# STM32H533 register map
File version: 1.3
CPU: CM33 r0p0, little endian, MPU, FPU, 4 interrupt priority bits
Registers are 32-bit, read-write, reset 0x0 unless marked. A register's access mark holds for its fields unless they carry their own. Offsets are from the block's base; [hi:lo] are bit positions; {n}, {i} and the like mark numbered series.

## ADCC — ADC common registers block
Base 0x42028300
Same registers: SEC_ADCC 0x52028300
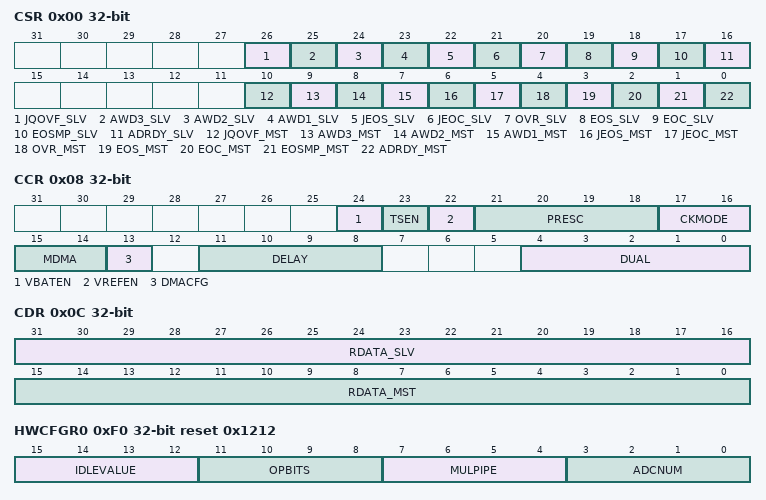
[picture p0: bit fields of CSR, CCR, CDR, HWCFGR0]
0x00 CSR ro — ADC common status register
  [26] JQOVF_SLV — Injected Context Queue Overflow flag of the slave ADC
  [25] AWD3_SLV — Analog watchdog 3 flag of the slave ADC
  [24] AWD2_SLV — Analog watchdog 2 flag of the slave ADC
  [23] AWD1_SLV — Analog watchdog 1 flag of the slave ADC
  [22] JEOS_SLV — End of injected sequence flag of the slave ADC
  [21] JEOC_SLV — End of injected conversion flag of the slave ADC
  [20] OVR_SLV — Overrun flag of the slave ADC
  [19] EOS_SLV — End of regular sequence flag of the slave ADC.
  [18] EOC_SLV — End of regular conversion of the slave ADC
  [17] EOSMP_SLV — End of Sampling phase flag of the slave ADC
  [16] ADRDY_SLV — Slave ADC ready
  [10] JQOVF_MST — Injected Context Queue Overflow flag of the master ADC
  [9] AWD3_MST — Analog watchdog 3 flag of the master ADC
  [8] AWD2_MST — Analog watchdog 2 flag of the master ADC
  [7] AWD1_MST — Analog watchdog 1 flag of the master ADC
  [6] JEOS_MST — End of injected sequence flag of the master ADC
  [5] JEOC_MST — End of injected conversion flag of the master ADC
  [4] OVR_MST — Overrun flag of the master ADC
  [3] EOS_MST — End of regular sequence flag of the master ADC
  [2] EOC_MST — End of regular conversion of the master ADC
  [1] EOSMP_MST — End of Sampling phase flag of the master ADC
  [0] ADRDY_MST — Master ADC ready
0x08 CCR — ADC common control register
  [24] VBATEN — VBAT enable
  [23] TSEN — Vless thansub>SENSEless than/sub> enable
  [22] VREFEN — Vless thansub>REFINTless than/sub> enable
  [21:18] PRESC — ADC prescaler
  [17:16] CKMODE — ADC clock mode
  [15:14] MDMA — Direct memory access mode for dual ADC mode
  [13] DMACFG — DMA configuration (for dual ADC mode)
  [11:8] DELAY — Delay between 2 sampling phases
  [4:0] DUAL — Dual ADC mode selection
0x0C CDR ro — ADC common regular data register for dual mode
  [31:16] RDATA_SLV — Regular data of the slave ADC
  [15:0] RDATA_MST — Regular data of the master ADC.
0xF0 HWCFGR0 ro reset 0x1212 — ADC hardware configuration register
  [15:12] IDLEVALUE — Idle value for non-selected channels
  [11:8] OPBITS — Number of option bits
  [7:4] MULPIPE — Number of pipeline stages
  [3:0] ADCNUM — Number of ADCs implemented
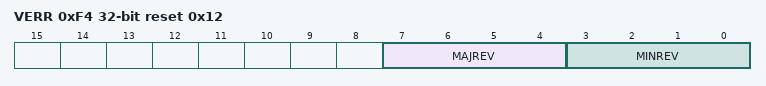
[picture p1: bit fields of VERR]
0xF4 VERR ro reset 0x12 — ADC version register
  [7:4] MAJREV — Major revision
  [3:0] MINREV — Minor revision
0xF8 IPDR ro reset 0x110006 — ADC identification register
  [31:0] ID — Peripheral identifier
0xFC SIDR ro reset 0xA3C5DD01 — ADC size identification register
  [31:0] SID — Size Identification

## AES — AES register block
Base 0x420C0000
Same registers: AES_S 0x520C0000
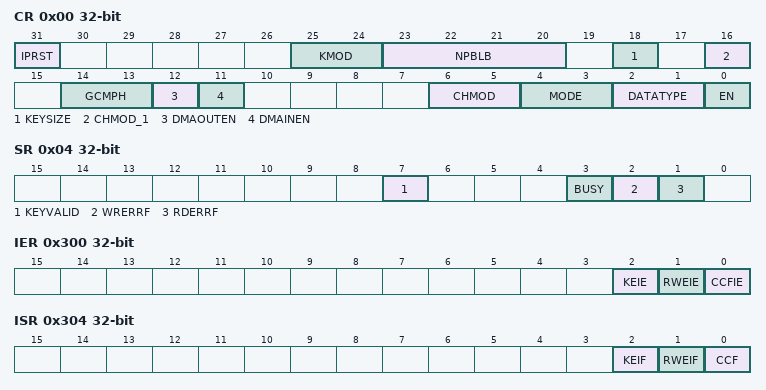
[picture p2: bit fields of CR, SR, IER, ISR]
0x00 CR — AES control register
  [31] IPRST — AES peripheral software reset
  [25:24] KMOD — Key mode selection
  [23:20] NPBLB — Number of padding bytes in last block
  [18] KEYSIZE — Key size selection
  [16] CHMOD_1 — CHMOD[2]
  [14:13] GCMPH — GCM or CCM phase selection
  [12] DMAOUTEN — DMA output enable
  [11] DMAINEN — DMA input enable
  [6:5] CHMOD — CHMOD[1:0]: Chaining mode
  [4:3] MODE — Operating mode
  [2:1] DATATYPE
  [0] EN — Enable
0x04 SR ro — AES status register
  [7] KEYVALID — Key valid flag
  [3] BUSY
  [2] WRERRF — Write error flag
  [1] RDERRF — Read error flag
0x08 DINR wo — AES data input register
  [31:0] DIN — Data input
0x0C DOUTR ro — AES data output register
  [31:0] DOUT — Data output
{0x10+4i} KEYR{i} wo (i=0..3) — AES key register {i}
  [31:0] KEY — Cryptographic key, bits [{32i+31}:{32i}]
{0x20+4i} IVR{i} (i=0..3) — AES initialization vector register {i}
  [31:0] IVI — Initialization vector input, bits [{32i+31}:{32i}]
{0x20+4i} KEYR{i} wo (i=4..7) — AES key register {i}
  [31:0] KEY — Cryptographic key, bits [{32i+31}:{32i}]
{0x40+4i} SUSPR{i} (i=0..7) — AES suspend registers
  [31:0] SUSP — Suspend data
0x300 IER — AES interrupt enable register
  [2] KEIE — Key error interrupt enable
  [1] RWEIE — Read or write error interrupt enable
  [0] CCFIE — Computation complete flag interrupt enable
0x304 ISR ro — AES interrupt status register
  [2] KEIF — Key error interrupt flag
  [1] RWEIF — Read or write error interrupt flag
  [0] CCF — Computation complete flag
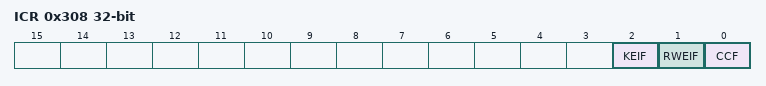
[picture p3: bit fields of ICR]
0x308 ICR wo — AES interrupt clear register
  [2] KEIF — Key error interrupt flag clear
  [1] RWEIF — Read or write error interrupt flag clear
  [0] CCF — Computation complete flag clear

## SAES — SAES register block
Base 0x420C0C00
Same registers: SAES_S 0x520C0C00
Registers as AES (with AES read as SAES); these are added or differ:
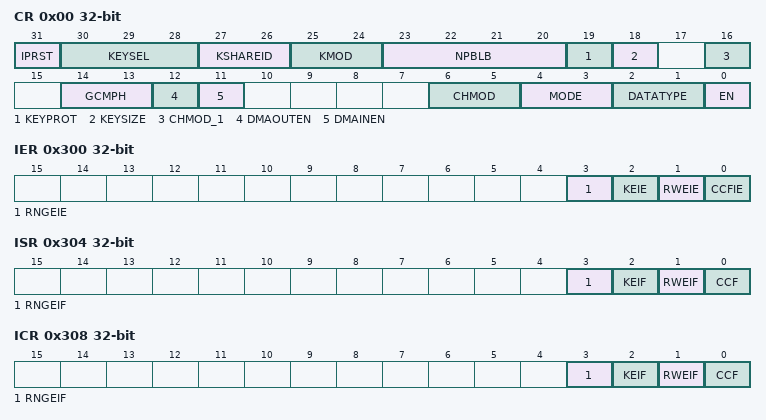
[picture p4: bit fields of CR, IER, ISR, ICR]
0x00 CR — SAES control register
  [31] IPRST — SAES peripheral software reset
  [30:28] KEYSEL — Key selection
  [27:26] KSHAREID — Key share identification
  [25:24] KMOD — Key mode selection
  [23:20] NPBLB — Number of padding bytes in last block
  [19] KEYPROT — Key protection
  [18] KEYSIZE — Key size selection
  [16] CHMOD_1 — CHMOD[2]
  [14:13] GCMPH — GCM or CCM phase selection
  [12] DMAOUTEN — DMA output enable
  [11] DMAINEN — DMA input enable
  [6:5] CHMOD — CHMOD[1:0]: Chaining mode
  [4:3] MODE — Operating mode
  [2:1] DATATYPE
  [0] EN — Enable
0x300 IER — SAES interrupt enable register
  [3] RNGEIE — RNG error interrupt enable
  [2] KEIE — Key error interrupt enable
  [1] RWEIE — Read or write error interrupt enable
  [0] CCFIE — Computation complete flag interrupt enable
0x304 ISR ro — SAES interrupt status register
  [3] RNGEIF — RNG error interrupt flag
  [2] KEIF — Key error interrupt flag
  [1] RWEIF — Read or write error interrupt flag
  [0] CCF — Computation complete flag
0x308 ICR wo — SAES interrupt clear register
  [3] RNGEIF — RNG error interrupt flag clear
  [2] KEIF — Key error interrupt flag clear
  [1] RWEIF — Read or write error interrupt flag clear
  [0] CCF — Computation complete flag clear
